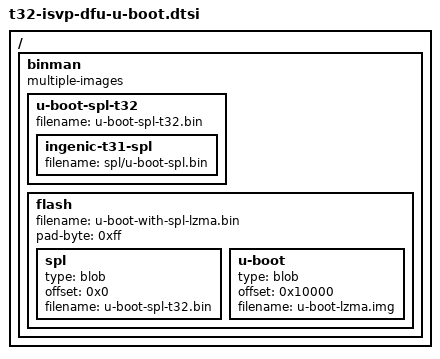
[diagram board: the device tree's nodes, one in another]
// SPDX-License-Identifier: GPL-2.0+
/*
 * Binman image description for the Ingenic ISVP-T32 DFU loader.
 *
 * The USB-boot path uploads spl/u-boot-spl.bin + u-boot.bin
 * directly via the mask ROM (tools/t31-usbboot.py - the protocol
 * is XBurst1-generic and works for T32 too), so the binman flash
 * images here are not used in the USB-boot flow. They are kept
 * consistent with the production t32-isvp layout (LZMA U-Boot at
 * 0x10000) so a stray `make` still produces a sensible flash
 * image. Outputs:
 *
 *   u-boot-spl-t32.bin       : SPL with the finalized SFC-NOR boot
 *                              header (CRC7 + image length).
 *   u-boot-with-spl-lzma.bin : headered SPL at offset 0 + LZMA
 *                              U-Boot at the SPL-loader offset
 *                              (no 0xff padding).
 */

/ {
	binman: binman {
		multiple-images;
	};
};

&binman {
	u-boot-spl-t32 {
		filename = "u-boot-spl-t32.bin";

		ingenic-t31-spl {
			filename = "spl/u-boot-spl.bin";
		};
	};

	flash {
		filename = "u-boot-with-spl-lzma.bin";
		pad-byte = <0xff>;

		spl {
			type = "blob";
			offset = <0x0>;
			filename = "u-boot-spl-t32.bin";
		};

		u-boot {
			type = "blob";
			offset = <0x10000>;
			filename = "u-boot-lzma.img";
		};
	};
};
